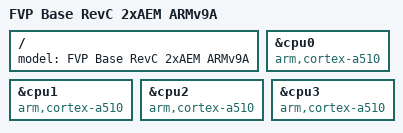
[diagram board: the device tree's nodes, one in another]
/*
 * Copyright (c) 2025 BayLibre SAS
 * SPDX-License-Identifier: Apache-2.0
 */

/dts-v1/;

#include <arm64/armv9-a.dtsi>
#include "fvp_base_revc_2xaem.dtsi"

/ {
	model = "FVP Base RevC 2xAEM ARMv9A";
};

&cpu0 {
	compatible = "arm,cortex-a510";
};

&cpu1 {
	compatible = "arm,cortex-a510";
};

&cpu2 {
	compatible = "arm,cortex-a510";
};

&cpu3 {
	compatible = "arm,cortex-a510";
};
